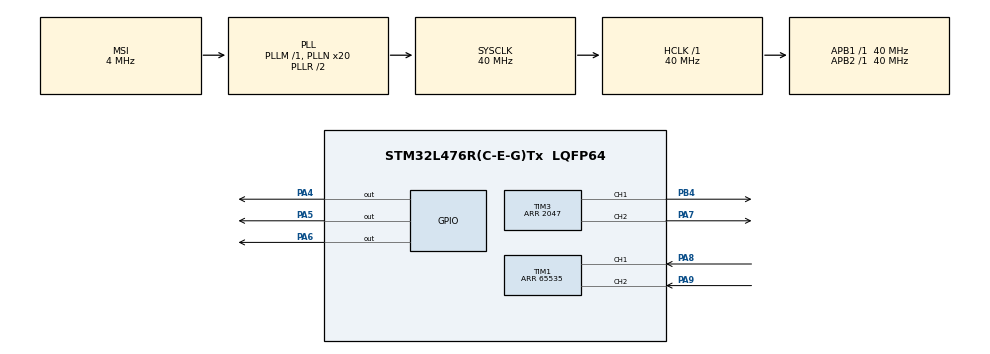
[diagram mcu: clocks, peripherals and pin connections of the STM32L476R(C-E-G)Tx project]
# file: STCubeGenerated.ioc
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Mcu.Family=STM32L4
Mcu.Name=STM32L476R(C-E-G)Tx
Mcu.Package=LQFP64
NVIC.PriorityGroup=NVIC_PRIORITYGROUP_4
PA13\ (JTMS-SWDIO).Mode=Trace_Asynchronous_SW
PA13\ (JTMS-SWDIO).Signal=SYS_JTMS-SWDIO
PA14\ (JTCK-SWCLK).Mode=Trace_Asynchronous_SW
PA14\ (JTCK-SWCLK).Signal=SYS_JTCK-SWCLK
PA4.Signal=GPIO_Output
PA5.Signal=GPIO_Output
PA6.Signal=GPIO_Output
PA7.Signal=S_TIM3_CH2
PA8.Signal=S_TIM1_CH1
PA9.Signal=S_TIM1_CH2
PB3\ (JTDO-TRACESWO).Mode=Trace_Asynchronous_SW
PB3\ (JTDO-TRACESWO).Signal=SYS_JTDO-SWO
PB4\ (NJTRST).Signal=S_TIM3_CH1
PH0-OSC_IN\ (PH0).Mode=HSE-External-Oscillator
PH0-OSC_IN\ (PH0).Signal=RCC_OSC_IN
PH1-OSC_OUT\ (PH1).Mode=HSE-External-Oscillator
PH1-OSC_OUT\ (PH1).Signal=RCC_OSC_OUT
ProjectManager.HeapSize=0x200
ProjectManager.StackSize=0x400
ProjectManager.TargetToolchain=MDK-ARM V5
RCC.AHBFreq_Value=40000000
RCC.APB1Freq_Value=40000000
RCC.APB1TimFreq_Value=40000000
RCC.APB2Freq_Value=40000000
RCC.APB2TimFreq_Value=40000000
RCC.CortexFreq_Value=40000000
RCC.HCLKFreq_Value=40000000
RCC.HSE_VALUE=8000000
RCC.HSI_VALUE=16000000
RCC.LSE_VALUE=32768
RCC.MSI_VALUE=4000000
RCC.PLLN=20
RCC.SYSCLKFreq_VALUE=40000000
RCC.SYSCLKSource=RCC_SYSCLKSOURCE_PLLCLK
RCC.VCOOutputFreq_Value=80000000
SH.S_TIM1_CH1.0=TIM1_CH1,Encoder_Interface
SH.S_TIM1_CH2.0=TIM1_CH2,Encoder_Interface
SH.S_TIM3_CH1.0=TIM3_CH1,PWM Generation1 CH1
SH.S_TIM3_CH2.0=TIM3_CH2,PWM Generation2 CH2
TIM1.EncoderMode=TIM_ENCODERMODE_TI12
TIM1.Period=65535
TIM3.Channel-PWM\ Generation1\ CH1=TIM_CHANNEL_1
TIM3.Channel-PWM\ Generation2\ CH2=TIM_CHANNEL_2
TIM3.Period=2047
board=custom

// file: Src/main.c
/* USER CODE BEGIN Header */
/**
  ******************************************************************************
  * @file           : main.c
  * @brief          : Main program body
  ******************************************************************************
  * @attention
  *
  * <h2><center>&copy; Copyright (c) 2026 STMicroelectronics.
  * All rights reserved.</center></h2>
  *
  * This software component is licensed by ST under BSD 3-Clause license,
  * the "License"; You may not use this file except in compliance with the
  * License. You may obtain a copy of the License at:
  *                        opensource.org/licenses/BSD-3-Clause
  *
  ******************************************************************************
  */
/* USER CODE END Header */

#include "main.h"

/* USER CODE BEGIN Includes */
#include <stdio.h>
#include "application.h"
/* USER CODE END Includes */

TIM_HandleTypeDef htim1;
TIM_HandleTypeDef htim3;

void SystemClock_Config(void);
static void MX_GPIO_Init(void);
static void MX_TIM1_Init(void);
static void MX_TIM3_Init(void);

/* USER CODE BEGIN 0 */
uint32_t Main_GetTickMillisec(void) {return HAL_GetTick();}
/* USER CODE END 0 */

int main(void)
{

  /* MCU Configuration--------------------------------------------------------*/

  /* Reset of all peripherals, Initializes the Flash interface and the Systick. */
  HAL_Init();

  /* Configure the system clock */
  SystemClock_Config();

  /* Initialize all configured peripherals */
  MX_GPIO_Init();
  MX_TIM1_Init();
  MX_TIM3_Init();
/* USER CODE BEGIN 2 */
Application_Setup();
/* USER CODE END 2 */

  /* Infinite loop */
/* USER CODE BEGIN WHILE */
while (1)
{
  Application_Loop();
  /* USER CODE END WHILE */

}
}

void SystemClock_Config(void)
{
  RCC_OscInitTypeDef RCC_OscInitStruct = {0};
  RCC_ClkInitTypeDef RCC_ClkInitStruct = {0};

  /** Initializes the CPU, AHB and APB busses clocks
  */
  RCC_OscInitStruct.OscillatorType = RCC_OSCILLATORTYPE_MSI;
  RCC_OscInitStruct.MSIState = RCC_MSI_ON;
  RCC_OscInitStruct.MSICalibrationValue = 0;
  RCC_OscInitStruct.MSIClockRange = RCC_MSIRANGE_6;
  RCC_OscInitStruct.PLL.PLLState = RCC_PLL_ON;
  RCC_OscInitStruct.PLL.PLLSource = RCC_PLLSOURCE_MSI;
  RCC_OscInitStruct.PLL.PLLM = 1;
  RCC_OscInitStruct.PLL.PLLN = 20;
  RCC_OscInitStruct.PLL.PLLP = RCC_PLLP_DIV7;
  RCC_OscInitStruct.PLL.PLLQ = RCC_PLLQ_DIV2;
  RCC_OscInitStruct.PLL.PLLR = RCC_PLLR_DIV2;
  if (HAL_RCC_OscConfig(&RCC_OscInitStruct) != HAL_OK)
  {
    Error_Handler();
  }
  /** Initializes the CPU, AHB and APB busses clocks
  */
  RCC_ClkInitStruct.ClockType = RCC_CLOCKTYPE_HCLK|RCC_CLOCKTYPE_SYSCLK
                              |RCC_CLOCKTYPE_PCLK1|RCC_CLOCKTYPE_PCLK2;
  RCC_ClkInitStruct.SYSCLKSource = RCC_SYSCLKSOURCE_PLLCLK;
  RCC_ClkInitStruct.AHBCLKDivider = RCC_SYSCLK_DIV1;
  RCC_ClkInitStruct.APB1CLKDivider = RCC_HCLK_DIV1;
  RCC_ClkInitStruct.APB2CLKDivider = RCC_HCLK_DIV1;

  if (HAL_RCC_ClockConfig(&RCC_ClkInitStruct, FLASH_LATENCY_2) != HAL_OK)
  {
    Error_Handler();
  }
  /** Configure the main internal regulator output voltage
  */
  if (HAL_PWREx_ControlVoltageScaling(PWR_REGULATOR_VOLTAGE_SCALE1) != HAL_OK)
  {
    Error_Handler();
  }
}

static void MX_TIM1_Init(void)
{

  TIM_Encoder_InitTypeDef sConfig = {0};
  TIM_MasterConfigTypeDef sMasterConfig = {0};

  htim1.Instance = TIM1;
  htim1.Init.Prescaler = 0;
  htim1.Init.CounterMode = TIM_COUNTERMODE_UP;
  htim1.Init.Period = 65535;
  htim1.Init.ClockDivision = TIM_CLOCKDIVISION_DIV1;
  htim1.Init.RepetitionCounter = 0;
  htim1.Init.AutoReloadPreload = TIM_AUTORELOAD_PRELOAD_DISABLE;
  sConfig.EncoderMode = TIM_ENCODERMODE_TI12;
  sConfig.IC1Polarity = TIM_ICPOLARITY_RISING;
  sConfig.IC1Selection = TIM_ICSELECTION_DIRECTTI;
  sConfig.IC1Prescaler = TIM_ICPSC_DIV1;
  sConfig.IC1Filter = 0;
  sConfig.IC2Polarity = TIM_ICPOLARITY_RISING;
  sConfig.IC2Selection = TIM_ICSELECTION_DIRECTTI;
  sConfig.IC2Prescaler = TIM_ICPSC_DIV1;
  sConfig.IC2Filter = 0;
  if (HAL_TIM_Encoder_Init(&htim1, &sConfig) != HAL_OK)
  {
    Error_Handler();
  }
  sMasterConfig.MasterOutputTrigger = TIM_TRGO_RESET;
  sMasterConfig.MasterOutputTrigger2 = TIM_TRGO2_RESET;
  sMasterConfig.MasterSlaveMode = TIM_MASTERSLAVEMODE_DISABLE;
  if (HAL_TIMEx_MasterConfigSynchronization(&htim1, &sMasterConfig) != HAL_OK)
  {
    Error_Handler();
  }
/* USER CODE BEGIN TIM1_Init 2 */
HAL_TIM_Encoder_Start(&htim1,TIM_CHANNEL_1);
HAL_TIM_Encoder_Start(&htim1,TIM_CHANNEL_2);
/* USER CODE END TIM1_Init 2 */

}

static void MX_TIM3_Init(void)
{

  TIM_MasterConfigTypeDef sMasterConfig = {0};
  TIM_OC_InitTypeDef sConfigOC = {0};

  htim3.Instance = TIM3;
  htim3.Init.Prescaler = 0;
  htim3.Init.CounterMode = TIM_COUNTERMODE_UP;
  htim3.Init.Period = 2047;
  htim3.Init.ClockDivision = TIM_CLOCKDIVISION_DIV1;
  htim3.Init.AutoReloadPreload = TIM_AUTORELOAD_PRELOAD_DISABLE;
  if (HAL_TIM_PWM_Init(&htim3) != HAL_OK)
  {
    Error_Handler();
  }
  sMasterConfig.MasterOutputTrigger = TIM_TRGO_RESET;
  sMasterConfig.MasterSlaveMode = TIM_MASTERSLAVEMODE_DISABLE;
  if (HAL_TIMEx_MasterConfigSynchronization(&htim3, &sMasterConfig) != HAL_OK)
  {
    Error_Handler();
  }
  sConfigOC.OCMode = TIM_OCMODE_PWM1;
  sConfigOC.Pulse = 0;
  sConfigOC.OCPolarity = TIM_OCPOLARITY_HIGH;
  sConfigOC.OCFastMode = TIM_OCFAST_DISABLE;
  if (HAL_TIM_PWM_ConfigChannel(&htim3, &sConfigOC, TIM_CHANNEL_1) != HAL_OK)
  {
    Error_Handler();
  }
  if (HAL_TIM_PWM_ConfigChannel(&htim3, &sConfigOC, TIM_CHANNEL_2) != HAL_OK)
  {
    Error_Handler();
  }
/* USER CODE BEGIN TIM3_Init 2 */
HAL_TIM_PWM_Start(&htim3, TIM_CHANNEL_1);
HAL_TIM_PWM_Start(&htim3, TIM_CHANNEL_2);
/* USER CODE END TIM3_Init 2 */
  HAL_TIM_MspPostInit(&htim3);

}

static void MX_GPIO_Init(void)
{
  GPIO_InitTypeDef GPIO_InitStruct = {0};

  /* GPIO Ports Clock Enable */
  __HAL_RCC_GPIOH_CLK_ENABLE();
  __HAL_RCC_GPIOA_CLK_ENABLE();
  __HAL_RCC_GPIOB_CLK_ENABLE();

  /*Configure GPIO pin Output Level */
  HAL_GPIO_WritePin(GPIOA, GPIO_PIN_4|GPIO_PIN_5|GPIO_PIN_6, GPIO_PIN_RESET);

  /*Configure GPIO pins : PA4 PA5 PA6 */
  GPIO_InitStruct.Pin = GPIO_PIN_4|GPIO_PIN_5|GPIO_PIN_6;
  GPIO_InitStruct.Mode = GPIO_MODE_OUTPUT_PP;
  GPIO_InitStruct.Pull = GPIO_NOPULL;
  GPIO_InitStruct.Speed = GPIO_SPEED_FREQ_LOW;
  HAL_GPIO_Init(GPIOA, &GPIO_InitStruct);

}

void Error_Handler(void)
{
}

/************************ (C) COPYRIGHT STMicroelectronics *****END OF FILE****/
